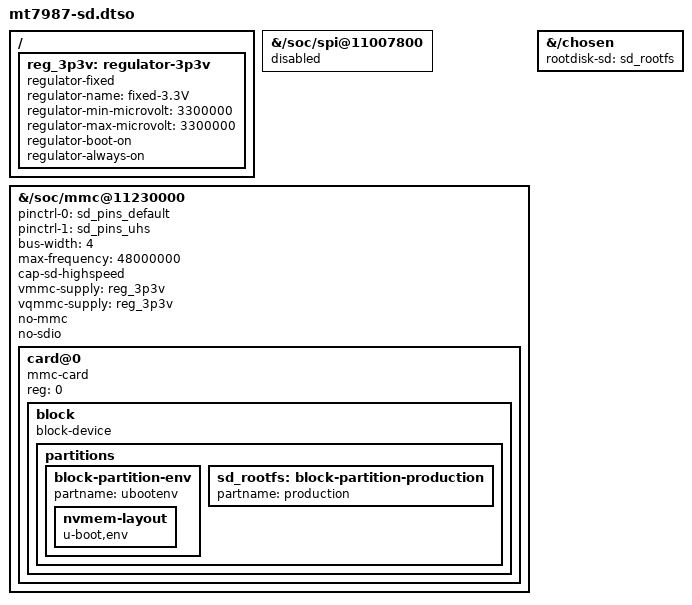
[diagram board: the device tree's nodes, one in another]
// SPDX-License-Identifier: (GPL-2.0 OR MIT)

/dts-v1/;
/plugin/;

/ {
	fragment@0 {
		target-path = "/";
		__overlay__ {
			reg_3p3v: regulator-3p3v {
				compatible = "regulator-fixed";
				regulator-name = "fixed-3.3V";
				regulator-min-microvolt = <3300000>;
				regulator-max-microvolt = <3300000>;
				regulator-boot-on;
				regulator-always-on;
			};
		};
	};

	fragment@1 {
		target-path = "/soc/spi@11007800";
		__overlay__ {
			status = "disabled";
		};
	};

	fragment@2 {
		target-path = "/soc/mmc@11230000";
		__overlay__ {
			pinctrl-names = "default", "state_uhs";
			pinctrl-0 = <&sd_pins_default>;
			pinctrl-1 = <&sd_pins_uhs>;
			bus-width = <4>;
			max-frequency = <48000000>;
			cap-sd-highspeed;
			vmmc-supply = <&reg_3p3v>;
			vqmmc-supply = <&reg_3p3v>;
			no-mmc;
			no-sdio;
			status = "okay";
			#address-cells = <1>;
			#size-cells = <0>;

			card@0 {
				compatible = "mmc-card";
				reg = <0>;

				block {
					compatible = "block-device";
					partitions {
						block-partition-env {
							partname = "ubootenv";
							nvmem-layout {
								compatible = "u-boot,env";
							};
						};
						sd_rootfs: block-partition-production {
							partname = "production";
						};
					};
				};
			};
		};
	};

        fragment@3 {
		target-path = "/chosen";
		__overlay__ {
			rootdisk-sd = <&sd_rootfs>;
		};
	};
};

